# RS1xxxx register map
Vendor: Silicon Lab Inc.; Series: ARMCM4; File version: 1.2
CPU: CM4 r1p0, little endian, MPU, FPU, 6 interrupt priority bits
Registers are 32-bit, read-write, reset 0x0 unless marked. A register's access mark holds for its fields unless they carry their own. Offsets are from the block's base; [hi:lo] are bit positions; lines under a group give offsets from that group; {n}, {i} and the like mark numbered series; 'fields as' and 'values as' point back to an identical list.

## EGPIO — ENHANCED GENERAL PERPOSE INPUT/OUTPUT
Base 0x46130000
{0x0+0x10*i} PIN_CONFIGn[{i}] (i=0..79) group — Pin configuration registers(0-79)
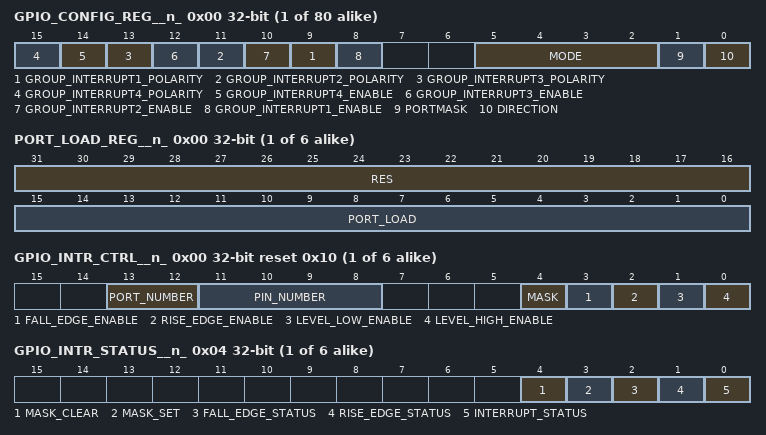
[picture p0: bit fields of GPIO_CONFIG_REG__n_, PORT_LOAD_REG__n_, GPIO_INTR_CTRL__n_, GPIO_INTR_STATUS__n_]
  0x00 GPIO_CONFIG_REG__n_ — GPIO Configuration Register
    [2n+7] GROUP_INTERRUPT{n}_POLARITY (n=1..4) — Decides the active value of the pin to be considered for group interrupt {n} generation
      0=Disable (group interrupt gets generated when gpio input pin status is zero); 1=Enable (grp interrupt gets generated when gpio input pin status is 1)
    [14] GROUP_INTERRUPT4_ENABLE — When set, the corresponding GPIO is pin is selected for group intr 4 generation
      1=enable the gpio group interrupt2; 0=disable the gpio group interrupt2
    [12] GROUP_INTERRUPT3_ENABLE — When set, the corresponding GPIO is pin is selected for group intr 3 generation
      values as GROUP_INTERRUPT4_ENABLE
    [10] GROUP_INTERRUPT2_ENABLE — When set, the corresponding GPIO is pin is selected for group intr 2 generation
      values as GROUP_INTERRUPT4_ENABLE
    [8] GROUP_INTERRUPT1_ENABLE — When set, the corresponding GPIO is pin is selected for group intr 1 generation
      1=enable the gpio group interrupt; 0=disable the gpio group interrupt1
    [5:2] MODE — GPIO Pin Mode Used for GPIO Pin Muxing
      0=000: Mode 0; 1=001:Mode 1; 2=010:Mode 2; 3=011:Mode 3; 4=100:Mode 4; 5=101: Mode 5; 6=110:Mode 6; 7=111:Mode 7
    [1] PORTMASK — Port mask value
    [0] DIRECTION — Direction of the GPIO pin
      0=Disable (Output); 1=Enable (Input)
  0x04 BIT_LOAD_REG__n_ — Bit Load
    [0] BIT_LOAD — Loads 0th bit on to the pin on write. And reads the value on pin on read into 0th bit
  0x08 WORD_LOAD_REG__n_ — Word Load
    [15:0] WORD_LOAD — Loads 1 on the pin when any of the bit in load value is 1. On read pass the bit status into all bits.
{0x1000+0x40*i} PORT_CONFIGn[{i}] (i=0..5) group — Port configuration registers (0-5)
  0x00 PORT_LOAD_REG__n_ (reset mask 0xFFFF) — Port Load
    [31:16] RES ro
    [15:0] PORT_LOAD — Loads the value on to pin on write. And reads the value of load register on read
  0x04 PORT_SET_REG__n_ wo — Port Set Register
    [15:0] PORT_SET — Sets the pin when corresponding bit is high. Writing zero has no effect.
  0x08 PORT_CLEAR_REG__n_ wo — Port Clear Register
    [15:0] PORT_CLEAR — Clears the pin when corresponding bit is high. Writing zero has no effect.
  0x0C PORT_MASKED_LOAD_REG__n_ wo — Port Masked Load Register
    [15:0] PORT_MASKED_LOAD — Only loads into pins which are not masked. On read, pass only status unmasked pins
  0x10 PORT_TOGGLE_REG__n_ wo — Port Toggle Register
    [15:0] PORT_TOGGLE — Toggles the pin when corresponding bit is high. Writing zero has not effect.
  0x14 PORT_READ_REG__n_ ro — Port Read Register
    [15:0] PORT_READ — Reads the value on GPIO pins irrespective of the pin mode.
{0x1200+8i} INTRn[{i}] (i=0..5) group — GPIO Interrupt related registers (0-5)
  0x00 GPIO_INTR_CTRL__n_ reset 0x10 — GPIO Interrupt Control Register
    [13:12] PORT_NUMBER — GPIO Port to be chosen for interrupt generation
    [11:8] PIN_NUMBER — GPIO Pin to be chosen for interrupt generation
    [4] MASK — Masks the interrupt. Interrupt will still be seen in status register when enabled
      0=Disable (Interrupt masked); 1=Enable (Interrupt unmasked)
    [3] FALL_EDGE_ENABLE — enables interrupt generation when Falling edge is detected on pin
      0=disabled; 1=Enable (Interrupt enabled)
    [2] RISE_EDGE_ENABLE — enables interrupt generation when rising edge is detected on pin
      0=disabled; 1=Enable (Interrupt enabled)
    [1] LEVEL_LOW_ENABLE — enables interrupt generation when pin level is 0
      0=disabled; 1=Enable (Interrupt enabled)
    [0] LEVEL_HIGH_ENABLE — enables interrupt generation when pin level is 1
      0=disabled; 1=Enable (Interrupt enabled)
  0x04 GPIO_INTR_STATUS__n_ — GPIO Interrupt Status Register
    [4] MASK_CLEAR wo
      0=Disable (On read, this bit should result it in 0); 1=Enable (When 1 is written mask bit gets cleared)
    [3] MASK_SET wo
      0=Disable (On read, this bit should result it in 0); 1=Enable (When 1 is written mask bit will get set)
    [2] FALL_EDGE_STATUS — Gets set when Fall edge is enabled and occurs.
      0=Disable (Writing 0 has not effect); 1=Enable (When 1 is written it gets cleared.)
    [1] RISE_EDGE_STATUS — Gets set when rise edge is enabled and occurs.
      values as FALL_EDGE_STATUS
    [0] INTERRUPT_STATUS — Gets set when interrupt is enabled and occurs.
      0=Disable (Writing 0 has not effect); 1=Enable (When 1 is written it gets cleared. Also clears rise edge and fall edge status bits)
{0x1240+8i} GPIO_GRP_INTRn[{i}] (i=0..3) group — GPIO Group interrupt related registers (0-3)
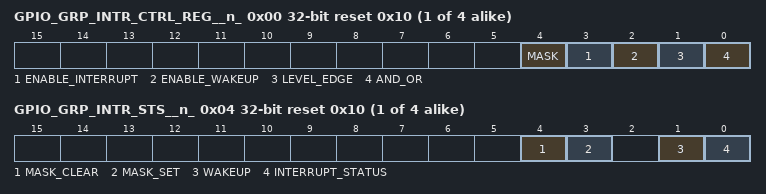
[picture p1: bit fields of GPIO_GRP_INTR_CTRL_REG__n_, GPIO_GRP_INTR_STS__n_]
  0x00 GPIO_GRP_INTR_CTRL_REG__n_ reset 0x10 — GPIO Interrupt 0 Control Register
    [4] MASK
      0=Disable (Mask); 1=Enable (unmask)
    [3] ENABLE_INTERRUPT
      0=Disable; 1=Enable
    [2] ENABLE_WAKEUP — For wakeup generation, actual pin status has to be seen(before double ranking point)
    [1] LEVEL_EDGE
      0=Disable (Level); 1=Enable (Edge)
    [0] AND_OR
      0=Disable (AND); 1=Enable (OR)
  0x04 GPIO_GRP_INTR_STS__n_ reset 0x10 — GPIO Interrupt 0 Status Register
    [4] MASK_CLEAR — Gives zero on read
    [3] MASK_SET — Gives zero on read
    [1] WAKEUP ro — Double ranked version of wakeup. Gets set when wakeup is enabled and occurs. When 1 is written it gets cleared
    [0] INTERRUPT_STATUS — Interrupt status is available in this bit when interrupt is enabled and generated. When 1 is written, interrupt gets cleared.
